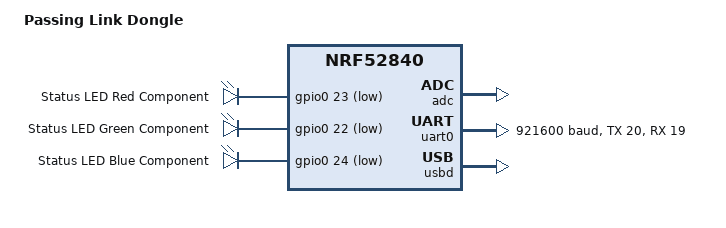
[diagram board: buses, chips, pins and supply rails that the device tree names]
/dts-v1/;
#include <nordic/nrf52840_qiaa.dtsi>

/ {
  model = "Passing Link Dongle";
  compatible = "nordic,nrf52840-qiaa", "nordic,nrf52840";

  aliases {
    tp-i2c = &i2c0;
  };

  chosen {
    zephyr,console = &uart0;
    zephyr,shell-uart = &uart0;
    zephyr,sram = &sram0;
    zephyr,flash = &flash0;
		zephyr,code-partition = &slot0_partition;
  };

  leds {
    compatible = "gpio-leds";
    led_status_r: led_0 {
      gpios = <&gpio0 23 GPIO_ACTIVE_LOW>;
      label = "Status LED Red Component";
    };
    led_status_g: led_1 {
      gpios = <&gpio0 22 GPIO_ACTIVE_LOW>;
      label = "Status LED Green Component";
    };
    led_status_b: led_2 {
      gpios = <&gpio0 24 GPIO_ACTIVE_LOW>;
      label = "Status LED Blue Component";
    };
  };
};

&adc {
  status = "okay";
};

&gpiote {
  status = "okay";
};

&gpio0 {
  status = "okay";
};

&gpio1 {
  status = "okay";
};

&uart0 {
  compatible = "nordic,nrf-uarte";
  current-speed = <921600>;
  status = "okay";
  tx-pin = <20>;
  rx-pin = <19>;
};

&usbd {
  compatible = "nordic,nrf-usbd";
  status = "okay";
};

#include "pl_nrf_partitions.dtsi"
